# FM33FG0XXA register map
File version: 1.0
CPU: SC000 r1p0, little endian, MPU, no FPU, 3 interrupt priority bits
Registers are 32-bit, read-only, reset 0x0 unless marked. A register's access mark holds for its fields unless they carry their own. Offsets are from the block's base; [hi:lo] are bit positions.

## SCU — SCU module information
Base 0x40000000
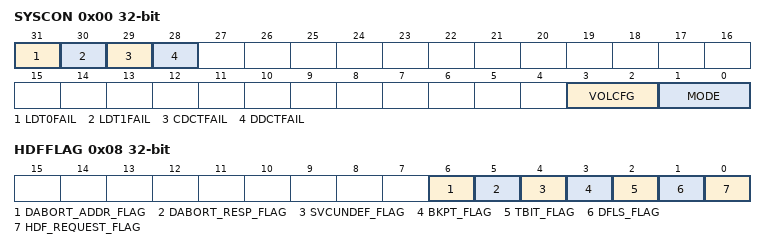
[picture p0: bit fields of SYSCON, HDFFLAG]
0x00 SYSCON — Memory Capacity Query Register
  [31] LDT0FAIL — LDT0FAIL field description
  [30] LDT1FAIL — LDT1FAIL field description
  [29] CDCTFAIL — CDCTFAIL field description
  [28] DDCTFAIL — DDCTFAIL field description
  [3:2] VOLCFG — VOLCFG field description
  [1:0] MODE — MODE field description
0x08 HDFFLAG rw — Hardfault Query Register
  [6] DABORT_ADDR_FLAG — DABORT_ADDR_FLAG field description
  [5] DABORT_RESP_FLAG — DABORT_RESP_FLAG field description
  [4] SVCUNDEF_FLAG — SVCUNDEF_FLAG field description
  [3] BKPT_FLAG — BKPT_FLAG field description
  [2] TBIT_FLAG — TBIT_FLAG field description
  [1] DFLS_FLAG — DFLS_FLAG field description
  [0] HDF_REQUEST_FLAG — HDF_REQUEST_FLAG field description

## IWDT — IWDT module information
Base 0x40011400
0x00 SERV wo — IWDT Service Register
  [31:0] SERV — SERV field description
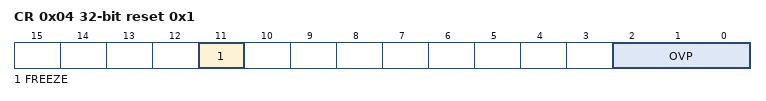
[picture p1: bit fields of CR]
0x04 CR rw reset 0x1 — IWDT Config Register
  [11] FREEZE — FREEZE field description
  [2:0] OVP — OVP field description
0x08 CNT — IWDT Counter Register
  [11:0] CNT — CNT field description
0x0C WIN rw — IWDT Window Register
  [11:0] WIN — WIN field description
0x10 IER rw — IWDT Interrupt Enable Register
  [0] IE — IE field description
0x14 ISR rw — IWDT Interrupt Status Register
  [0] WINF — WINF field description

## WWDT — WWDT module information
Base 0x40011800
0x00 CR wo — WWDT Control Register
  [7:0] CON — CON field description
0x04 CFGR rw reset 0x3 — WWDT Config Register
  [2:0] CFG — CFG field description
0x08 CNT — WWDT Counter Register
  [9:0] CNT — CNT field description
0x0C IER rw — WWDT Interrupt Enable Register
  [0] IE — IE field description
0x10 ISR rw — WWDT Interrupt Status Register
  [0] NOVF — NOVF field description
0x14 PSC — WWDT Prescaler Register
  [11:0] DIV_CNT — DIV_CNT field description

## CLM0 — CLM0 module information
Base 0x4001B800
Same registers: CLM1 0x4001BC00
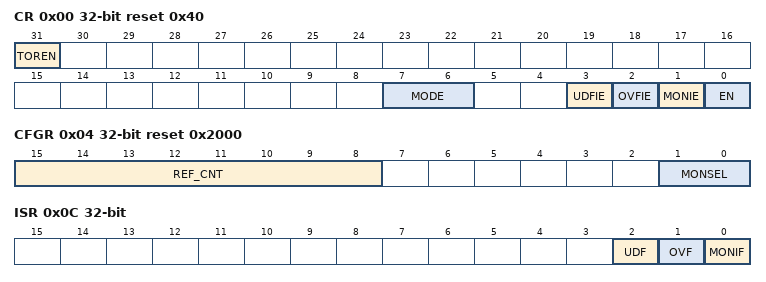
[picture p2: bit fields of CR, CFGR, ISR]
0x00 CR rw reset 0x40 — Clock Monitor Control Register
  [31] TOREN — TOREN field description
  [7:6] MODE — MODE field description
  [3] UDFIE — UDFIE field description
  [2] OVFIE — OVFIE field description
  [1] MONIE — MONIE field description
  [0] EN — EN field description
0x04 CFGR rw reset 0x2000 — Clock Monitor Configuration Register
  [15:8] REF_CNT — REF_CNT field description
  [1:0] MONSEL — MONSEL field description
0x08 CNTR rw — Clock Monitor Count Value Register
  [23:0] CNT — CNT field description
0x0C ISR rw — Clock Monitor Interrupt Flag Register
  [2] UDF — UDF field description
  [1] OVF — OVF field description
  [0] MONIF — MONIF field description
0x10 CMPH rw — Clock Monitor Compare High Threshold Register
  [23:0] CMPH — CMPH field description
0x14 CMPL rw — Clock Monitor Compare Low Threshold Register
  [23:0] CMPL — CMPL field description

## SVD — SVD module information
Base 0x40012800
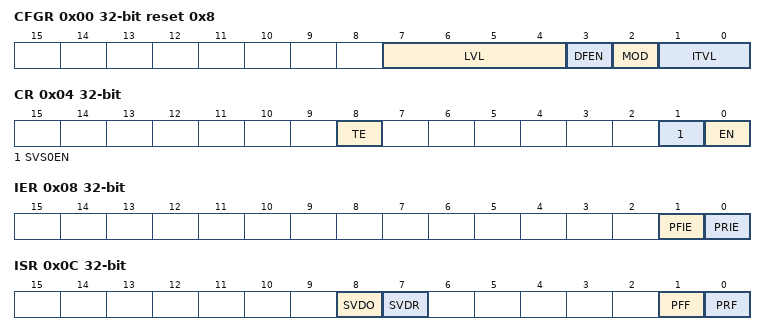
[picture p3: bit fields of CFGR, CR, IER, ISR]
0x00 CFGR rw reset 0x8 — SVD Config Register
  [7:4] LVL — LVL field description
  [3] DFEN — DFEN field description
  [2] MOD — MOD field description
  [1:0] ITVL — ITVL field description
0x04 CR rw — SVD Control Register
  [8] TE — TE field description
  [1] SVS0EN — SVS0EN field description
  [0] EN — EN field description
0x08 IER rw — SVD Interrupt Enable Register
  [1] PFIE — PFIE field description
  [0] PRIE — PRIE field description
0x0C ISR access per field — SVD Interrupt Status Register
  [8] SVDO ro — SVDO field description
  [7] SVDR ro — SVDR field description
  [1] PFF rw — PFF field description
  [0] PRF rw — PRF field description
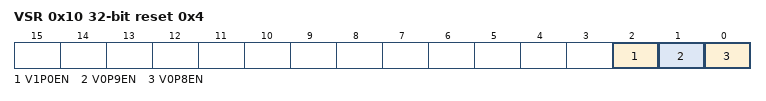
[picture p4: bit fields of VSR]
0x10 VSR rw reset 0x4 — SVD reference Voltage Select Register
  [2] V1P0EN — V1P0EN field description
  [1] V0P9EN — V0P9EN field description
  [0] V0P8EN — V0P8EN field description
